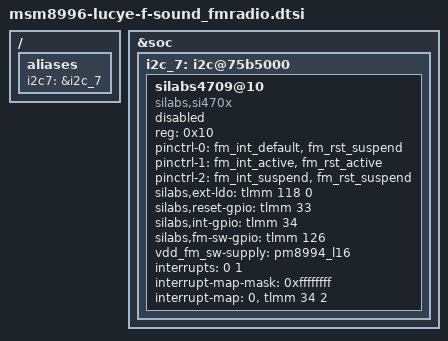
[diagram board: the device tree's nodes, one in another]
/* Copyright (c) 2015, The Linux Foundation. All rights reserved.
 *
 * This program is free software; you can redistribute it and/or modify
 * it under the terms of the GNU General Public License version 2 and
 * only version 2 as published by the Free Software Foundation.
 *
 * This program is distributed in the hope that it will be useful,
 * but WITHOUT ANY WARRANTY; without even the implied warranty of
 * MERCHANTABILITY or FITNESS FOR A PARTICULAR PURPOSE.  See the
 * GNU General Public License for more details.
 */

/{
	aliases {
		i2c7 = &i2c_7;
	};
};


&soc {

	i2c_7: i2c@75b5000 {
		silabs4709@10 { /* SiLabs FM si4709 chip, slave id 0x10*/
			status = "disabled";
			compatible = "silabs,si470x";
			#address-cells = <0>;
			reg = <0x10>;
			pinctrl-names = "default","pmx_fm_active","pmx_fm_suspend";
			pinctrl-0 = <&fm_int_default &fm_rst_suspend>;
			pinctrl-1 = <&fm_int_active &fm_rst_active>;
			pinctrl-2 = <&fm_int_suspend &fm_rst_suspend>;
			silabs,ext-ldo = <&tlmm 118 0>;
			silabs,reset-gpio = <&tlmm 33 0>;
			silabs,int-gpio = <&tlmm 34 0>;
			silabs,fm-sw-gpio = <&tlmm 126 0>;
			vdd_fm_sw-supply = <&pm8994_l16>;
			interrupts = <0 1>;
			#interrupt-cells = <1>;
			interrupt-map-mask = <0xffffffff>;
			interrupt-map = <
				  0 &tlmm 34 2
				>;
			interrupt-names = "silabs_fm_int", "silabs_fm_status_int";
		};
	};
};
